AUTOSAR XML (schema 4-0-3)
standard types defined: Boolean, UInt16, UInt32, UInt8
package /AUTOSAR_Platform/DataConstrs
  range DC_Boolean: raw 0..1
  range DC_UInt16: raw 0..65535
  range DC_UInt8: raw 0..255
package /PATAC/MSM/ComponentTypes
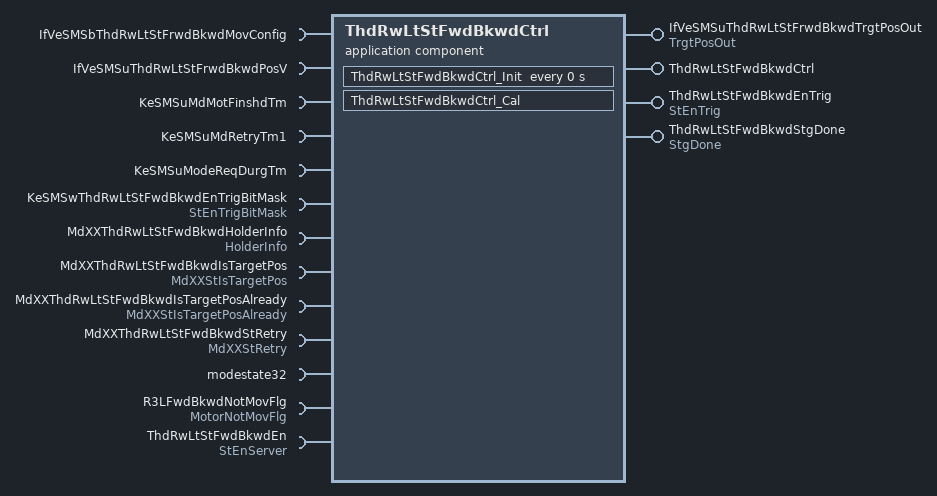
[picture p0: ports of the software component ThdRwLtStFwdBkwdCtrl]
  application sw component type ThdRwLtStFwdBkwdCtrl
    4 x provide port:
      IfVeSMSuThdRwLtStFrwdBkwdTrgtPosOut: nonqueued-sender-com-spec{data-element=TrgtPosOut/Val, init-value=0}, provided-interface=TrgtPosOut
      ThdRwLtStFwdBkwdCtrl: server-com-spec{operation=Cal, queue-length=1}, provided-interface=ThdRwLtStFwdBkwdCtrl
      ThdRwLtStFwdBkwdEnTrig: nonqueued-sender-com-spec{data-element=StEnTrig/Val, init-value=0}, provided-interface=StEnTrig
      ThdRwLtStFwdBkwdStgDone: nonqueued-sender-com-spec{data-element=StgDone/Val, init-value=0}, provided-interface=StgDone
    13 x require port:
      IfVeSMSbThdRwLtStFrwdBkwdMovConfig: nonqueued-receiver-com-spec{data-element=IfVeSMSbThdRwLtStFrwdBkwdMovConfig/Val, filter=data-filter-type=ALWAYS, init-value=0}, required-interface=IfVeSMSbThdRwLtStFrwdBkwdMovConfig
      IfVeSMSuThdRwLtStFrwdBkwdPosV: nonqueued-receiver-com-spec{data-element=IfVeSMSuThdRwLtStFrwdBkwdPosV/Val, filter=data-filter-type=ALWAYS, init-value=0}, required-interface=IfVeSMSuThdRwLtStFrwdBkwdPosV
      KeSMSuMdMotFinshdTm: parameter-require-com-spec{init-value=0, parameter=KeSMSuMdMotFinshdTm/Val}, required-interface=KeSMSuMdMotFinshdTm
      KeSMSuMdRetryTm1: parameter-require-com-spec{init-value=0, parameter=KeSMSuMdRetryTm1/Val}, required-interface=KeSMSuMdRetryTm1
      KeSMSuModeReqDurgTm: parameter-require-com-spec{init-value=0, parameter=KeSMSuModeReqDurgTm/Val}, required-interface=KeSMSuModeReqDurgTm
      KeSMSwThdRwLtStFwdBkwdEnTrigBitMask: parameter-require-com-spec{init-value=6153, parameter=StEnTrigBitMask/Val}, required-interface=StEnTrigBitMask
      MdXXThdRwLtStFwdBkwdHolderInfo: nonqueued-receiver-com-spec{data-element=HolderInfo/Val, filter=data-filter-type=ALWAYS, init-value=0}, required-interface=HolderInfo
      MdXXThdRwLtStFwdBkwdIsTargetPos: nonqueued-receiver-com-spec{data-element=MdXXStIsTargetPos/Val, filter=data-filter-type=ALWAYS, init-value=0}, required-interface=MdXXStIsTargetPos
      MdXXThdRwLtStFwdBkwdIsTargetPosAlready: nonqueued-receiver-com-spec{data-element=MdXXStIsTargetPosAlready/Val, filter=data-filter-type=ALWAYS, init-value=0}, required-interface=MdXXStIsTargetPosAlready
      MdXXThdRwLtStFwdBkwdStRetry: nonqueued-receiver-com-spec{data-element=MdXXStRetry/Val, filter=data-filter-type=ALWAYS, init-value=0}, required-interface=MdXXStRetry
      modestate32: nonqueued-receiver-com-spec{data-element=modestate32/Val, filter=data-filter-type=ALWAYS, init-value=0}, required-interface=modestate32
      R3LFwdBkwdNotMovFlg: nonqueued-receiver-com-spec{data-element=MotorNotMovFlg/Val, filter=data-filter-type=ALWAYS, init-value=0}, required-interface=MotorNotMovFlg
      ThdRwLtStFwdBkwdEn: required-com-specs=[Clear, Get, Set], required-interface=StEnServer
    behavior ThdRwLtStFwdBkwdCtrl_InternalBehavior
      operation invoked event OIT_ThdRwLtStFwdBkwdCtrl_Cal_ThdRwLtStFwdBkwdCtrl_Cal: start-on-event=ThdRwLtStFwdBkwdCtrl_Cal, operation=ThdRwLtStFwdBkwdCtrl.Cal
      timing event ThdRwLtStFwdBkwdCtrl_InitEvent: start-on-event=ThdRwLtStFwdBkwdCtrl_Init, period=0
      runnable ThdRwLtStFwdBkwdCtrl_Cal
        data-receive-point-by-arguments:
          8 x access:
            REC_IfVeSMSbThdRwLtStFrwdBkwdMovConfig_Val: accessed-variable=IfVeSMSbThdRwLtStFrwdBkwdMovConfig.Val
            REC_IfVeSMSuThdRwLtStFrwdBkwdPosV_Val: accessed-variable=IfVeSMSuThdRwLtStFrwdBkwdPosV.Val
            REC_MdXXThdRwLtStFwdBkwdHolderInfo_Val: accessed-variable=MdXXThdRwLtStFwdBkwdHolderInfo.Val
            REC_MdXXThdRwLtStFwdBkwdIsTargetPos_Val: accessed-variable=MdXXThdRwLtStFwdBkwdIsTargetPos.Val
            REC_MdXXThdRwLtStFwdBkwdIsTargetPosAlready_Val: accessed-variable=MdXXThdRwLtStFwdBkwdIsTargetPosAlready.Val
            REC_MdXXThdRwLtStFwdBkwdStRetry_Val: accessed-variable=MdXXThdRwLtStFwdBkwdStRetry.Val
            REC_modestate32_Val: accessed-variable=modestate32.Val
            REC_R3LFwdBkwdNotMovFlg_Val: accessed-variable=R3LFwdBkwdNotMovFlg.Val
        data-send-points:
          access SEND_IfVeSMSuThdRwLtStFrwdBkwdTrgtPosOut_Val: accessed-variable=IfVeSMSuThdRwLtStFrwdBkwdTrgtPosOut.Val
          access SEND_ThdRwLtStFwdBkwdEnTrig_Val: accessed-variable=ThdRwLtStFwdBkwdEnTrig.Val
          access SEND_ThdRwLtStFwdBkwdStgDone_Val: accessed-variable=ThdRwLtStFwdBkwdStgDone.Val
        4 x parameter access:
          PA_KeSMSuMdMotFinshdTm_Val: accessed-parameter=KeSMSuMdMotFinshdTm.Val
          PA_KeSMSuMdRetryTm1_Val: accessed-parameter=KeSMSuMdRetryTm1.Val
          PA_KeSMSuModeReqDurgTm_Val: accessed-parameter=KeSMSuModeReqDurgTm.Val
          PA_KeSMSwThdRwLtStFwdBkwdEnTrigBitMask_Val: accessed-parameter=KeSMSwThdRwLtStFwdBkwdEnTrigBitMask.Val
        sync call SC_ThdRwLtStFwdBkwdEn_Get: operation=ThdRwLtStFwdBkwdEn.Get, timeout=0
      runnable ThdRwLtStFwdBkwdCtrl_Init
        4 x parameter access:
          PA_KeSMSuMdMotFinshdTm_Val: accessed-parameter=KeSMSuMdMotFinshdTm.Val
          PA_KeSMSuMdRetryTm1_Val: accessed-parameter=KeSMSuMdRetryTm1.Val
          PA_KeSMSuModeReqDurgTm_Val: accessed-parameter=KeSMSuModeReqDurgTm.Val
          PA_KeSMSwThdRwLtStFwdBkwdEnTrigBitMask_Val: accessed-parameter=KeSMSwThdRwLtStFwdBkwdEnTrigBitMask.Val
  swc implementation ThdRwLtStFwdBkwdCtrl_Implementation: behavior=ThdRwLtStFwdBkwdCtrl_InternalBehavior
    code-descriptors:
      code Default: artifact-descriptors=autosar-engineering-object={short-label=Default, category=SWSRC}
package /PATAC/MSM/ModeAdjust/CalPortInterface
  parameter interface KeSMSuMdMotFinshdTm
    parameter data prototype Val: sw-calibration-access=READ-WRITE, type=UInt16
  parameter interface KeSMSuModeReqDurgTm
    parameter data prototype Val: sw-calibration-access=READ-WRITE, type=UInt16
  parameter interface StEnTrigBitMask
    parameter data prototype Val: sw-calibration-access=READ-WRITE, type=UInt32
package /PATAC/MSM/ModeAdjust/Interfaces
  sender receiver interface IfVeSMSuThdRwLtStFrwdBkwdPosV: invalidation-policy{data-element=IfVeSMSuThdRwLtStFrwdBkwdPosV/Val, handle-invalid=DONT-INVALIDATE}
    data Val: type=Boolean
package /PATAC/MSM/ModeAdjust/PortInterface
  client server interface StEnServer
    operation Clear
      arg data: type=UInt8, direction=IN, server-argument-impl-policy=USE-ARGUMENT-TYPE
    operation Get
      arg data: type=UInt32, direction=OUT, server-argument-impl-policy=USE-ARGUMENT-TYPE
    operation Set
      arg data: type=UInt8, direction=IN, server-argument-impl-policy=USE-ARGUMENT-TYPE
  client server interface ThdRwLtStFwdBkwdCtrl
    operation Cal
  9 x sender receiver interface:
    HolderInfo: invalidation-policy{data-element=HolderInfo/Val, handle-invalid=DONT-INVALIDATE}
      data Val: type=UInt32
    MdXXStIsTargetPos: invalidation-policy{data-element=MdXXStIsTargetPos/Val, handle-invalid=DONT-INVALIDATE}
      data Val: type=UInt32
    MdXXStIsTargetPosAlready: invalidation-policy{data-element=MdXXStIsTargetPosAlready/Val, handle-invalid=DONT-INVALIDATE}
      data Val: type=UInt32
    MdXXStRetry: invalidation-policy{data-element=MdXXStRetry/Val, handle-invalid=DONT-INVALIDATE}
      data Val: type=UInt32
    modestate32: invalidation-policy{data-element=modestate32/Val, handle-invalid=DONT-INVALIDATE}
      data Val: type=UInt32
    MotorNotMovFlg: invalidation-policy{data-element=MotorNotMovFlg/Val, handle-invalid=DONT-INVALIDATE}
      data Val: type=Boolean
    StEnTrig: invalidation-policy{data-element=StEnTrig/Val, handle-invalid=DONT-INVALIDATE}
      data Val: type=Boolean
    StgDone: invalidation-policy{data-element=StgDone/Val, handle-invalid=DONT-INVALIDATE}
      data Val: type=Boolean
    TrgtPosOut: invalidation-policy{data-element=TrgtPosOut/Val, handle-invalid=DONT-INVALIDATE}
      data Val: type=Boolean
package /PATAC/MSM/PortInterfaces
  parameter interface KeSMSuMdRetryTm1
    parameter data prototype Val: sw-calibration-access=READ-WRITE, type=UInt8
  sender receiver interface IfVeSMSbThdRwLtStFrwdBkwdMovConfig: invalidation-policy{data-element=IfVeSMSbThdRwLtStFrwdBkwdMovConfig/Val, handle-invalid=DONT-INVALIDATE}
    data Val: type=Boolean
